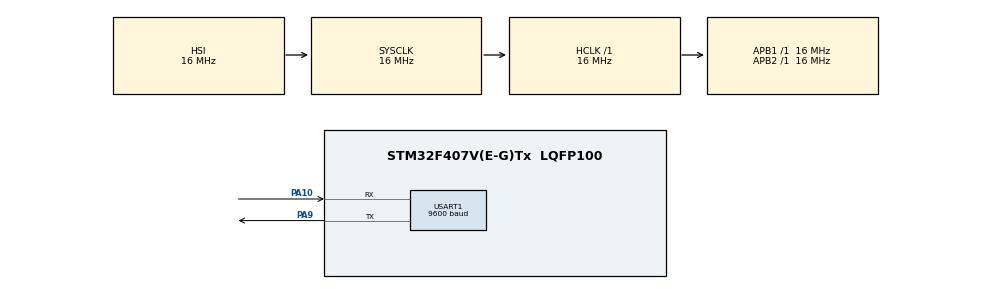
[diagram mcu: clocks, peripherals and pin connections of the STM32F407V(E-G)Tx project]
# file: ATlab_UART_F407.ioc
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Mcu.Family=STM32F4
Mcu.Name=STM32F407V(E-G)Tx
Mcu.Package=LQFP100
NVIC.PriorityGroup=NVIC_PRIORITYGROUP_4
PA10.Mode=Asynchronous
PA10.Signal=USART1_RX
PA13.Mode=Serial_Wire
PA13.Signal=SYS_JTMS-SWDIO
PA14.Mode=Serial_Wire
PA14.Signal=SYS_JTCK-SWCLK
PA9.Mode=Asynchronous
PA9.Signal=USART1_TX
ProjectManager.HeapSize=0x200
ProjectManager.StackSize=0x400
ProjectManager.TargetToolchain=STM32CubeIDE
RCC.AHBFreq_Value=16000000
RCC.APB1Freq_Value=16000000
RCC.APB2Freq_Value=16000000
RCC.CortexFreq_Value=16000000
RCC.HSE_VALUE=25000000
RCC.HSI_VALUE=16000000
RCC.LSE_VALUE=32768
RCC.SYSCLKFreq_VALUE=16000000
RCC.VCOOutputFreq_Value=192000000
USART1.BaudRate=9600
USART1.VirtualMode=VM_ASYNC
board=custom

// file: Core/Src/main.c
/* USER CODE BEGIN Header */
/**
 ******************************************************************************
 * @file           : main.c
 * @brief          : STM32F407 UART Bidirectional Communication
 *
 * Project         : ATlab_UART_F407
 * MCU             : STM32F407VET6
 * Peripheral      : USART1
 *
 * UART Settings:
 * Baud Rate       : 9600
 * Word Length     : 8 Bits
 * Parity          : None
 * Stop Bits       : 1
 *
 * TX Pin          : PA9
 * RX Pin          : PA10
 *
 * Communication:
 * STM32F407 sends "HELLO"
 * STM32L476 replies "ACK"
 *
 ******************************************************************************
 */
/* USER CODE END Header */

#include "main.h"

/* USER CODE BEGIN PD */

#define UART_TIMEOUT_MS 1000U
#define UART_DELAY_MS   1000U

/* USER CODE END PD */

UART_HandleTypeDef huart1;

/* USER CODE BEGIN PV */

/* UART transmission data */
uint8_t uart_hello[5] = {
    'H', 'E', 'L', 'L', 'O'
};

/* UART reception buffer */
uint8_t uart_ack[3] = {0};

/* Communication counters */
volatile uint32_t uart_ack_count = 0;
volatile uint32_t uart_error_count = 0;

/* Detailed error counters */
volatile uint32_t uart_tx_error_count = 0;
volatile uint32_t uart_rx_error_count = 0;
volatile uint32_t uart_invalid_ack_count = 0;

/* USER CODE END PV */

void SystemClock_Config(void);

static void MX_GPIO_Init(void);

static void MX_USART1_UART_Init(void);

int main(void)
{

    /* MCU Configuration----------------------------------------------------*/

    /* Reset of all peripherals */
    HAL_Init();

    /* Configure the system clock */
    SystemClock_Config();

    /* Initialize all configured peripherals */
    MX_GPIO_Init();
    MX_USART1_UART_Init();

    /* USER CODE BEGIN 2 */

    /*
     * Allow the other STM32 board
     * some time to initialize.
     */
    HAL_Delay(500);

    /* USER CODE END 2 */

    /* Infinite loop */

    while (1)
    {

        /* USER CODE BEGIN 3 */

        /*
         * Step 1:
         * Clear the reception buffer.
         */

        uart_ack[0] = 0;
        uart_ack[1] = 0;
        uart_ack[2] = 0;

        /*
         * Step 2:
         * Send "HELLO" to STM32L476.
         */

        HAL_StatusTypeDef tx_status;

        tx_status = HAL_UART_Transmit(
            &huart1,
            uart_hello,
            sizeof(uart_hello),
            UART_TIMEOUT_MS
        );

        if (tx_status == HAL_OK)
        {
            /*
             * Step 3:
             * Wait for "ACK" from STM32L476.
             */

            HAL_StatusTypeDef rx_status;

            rx_status = HAL_UART_Receive(
                &huart1,
                uart_ack,
                sizeof(uart_ack),
                UART_TIMEOUT_MS
            );

            if (rx_status == HAL_OK)
            {
                /*
                 * Step 4:
                 * Verify received ACK.
                 */

                if (
                    uart_ack[0] == 'A' &&
                    uart_ack[1] == 'C' &&
                    uart_ack[2] == 'K'
                )
                {
                    /*
                     * Communication successful.
                     */

                    uart_ack_count++;
                }
                else
                {
                    /*
                     * Invalid response received.
                     */

                    uart_invalid_ack_count++;
                    uart_error_count++;
                }
            }
            else
            {
                /*
                 * Reception failed or timed out.
                 */

                uart_rx_error_count++;
                uart_error_count++;
            }
        }
        else
        {
            /*
             * Transmission failed.
             */

            uart_tx_error_count++;
            uart_error_count++;
        }

        /*
         * Step 5:
         * Wait before the next transmission.
         */

        HAL_Delay(UART_DELAY_MS);

    }

    /* USER CODE END 3 */
}

void SystemClock_Config(void)
{
    RCC_OscInitTypeDef RCC_OscInitStruct = {0};
    RCC_ClkInitTypeDef RCC_ClkInitStruct = {0};

    /* Configure the main internal regulator output voltage */

    __HAL_RCC_PWR_CLK_ENABLE();

    __HAL_PWR_VOLTAGESCALING_CONFIG(
        PWR_REGULATOR_VOLTAGE_SCALE1
    );

    /* Initialize RCC Oscillators */

    RCC_OscInitStruct.OscillatorType =
        RCC_OSCILLATORTYPE_HSI;

    RCC_OscInitStruct.HSIState = RCC_HSI_ON;

    RCC_OscInitStruct.HSICalibrationValue =
        RCC_HSICALIBRATION_DEFAULT;

    RCC_OscInitStruct.PLL.PLLState = RCC_PLL_NONE;

    if (HAL_RCC_OscConfig(&RCC_OscInitStruct) != HAL_OK)
    {
        Error_Handler();
    }

    /* Initialize CPU, AHB and APB clocks */

    RCC_ClkInitStruct.ClockType =
        RCC_CLOCKTYPE_HCLK |
        RCC_CLOCKTYPE_SYSCLK |
        RCC_CLOCKTYPE_PCLK1 |
        RCC_CLOCKTYPE_PCLK2;

    RCC_ClkInitStruct.SYSCLKSource =
        RCC_SYSCLKSOURCE_HSI;

    RCC_ClkInitStruct.AHBCLKDivider =
        RCC_SYSCLK_DIV1;

    RCC_ClkInitStruct.APB1CLKDivider =
        RCC_HCLK_DIV1;

    RCC_ClkInitStruct.APB2CLKDivider =
        RCC_HCLK_DIV1;

    if (
        HAL_RCC_ClockConfig(
            &RCC_ClkInitStruct,
            FLASH_LATENCY_0
        ) != HAL_OK
    )
    {
        Error_Handler();
    }
}

static void MX_USART1_UART_Init(void)
{

    huart1.Instance = USART1;

    huart1.Init.BaudRate = 9600;

    huart1.Init.WordLength = UART_WORDLENGTH_8B;

    huart1.Init.StopBits = UART_STOPBITS_1;

    huart1.Init.Parity = UART_PARITY_NONE;

    huart1.Init.Mode = UART_MODE_TX_RX;

    huart1.Init.HwFlowCtl = UART_HWCONTROL_NONE;

    huart1.Init.OverSampling = UART_OVERSAMPLING_16;

    if (HAL_UART_Init(&huart1) != HAL_OK)
    {
        Error_Handler();
    }

}

static void MX_GPIO_Init(void)
{

    /* GPIO Ports Clock Enable */

    __HAL_RCC_GPIOA_CLK_ENABLE();

}

void Error_Handler(void)
{
    /* USER CODE BEGIN Error_Handler_Debug */

    /*
     * Disable interrupts and stop execution
     * when a critical error occurs.
     */

    __disable_irq();

    while (1)
    {
    }

    /* USER CODE END Error_Handler_Debug */
}
